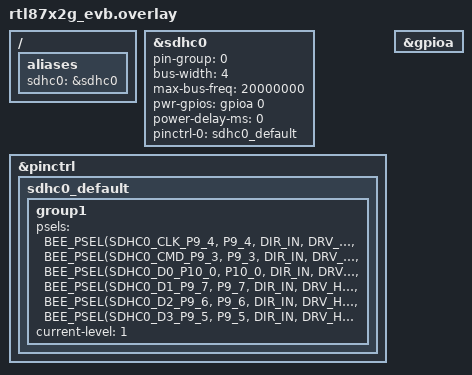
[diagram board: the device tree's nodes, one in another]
/*
 * Copyright(c) 2025, Realtek Semiconductor Corporation.
 *
 * SPDX-License-Identifier: Apache-2.0
 */

/ {
	aliases {
		sdhc0 = &sdhc0;
	};
};

&sdhc0 {
	pin-group = <0>;
	bus-width = <4>;
	max-bus-freq = <20000000>;
	pwr-gpios = <&gpioa 0 GPIO_ACTIVE_HIGH>;
	power-delay-ms = <0>;
	pinctrl-0 = <&sdhc0_default>;
	pinctrl-names = "default";
	status = "okay";
};

&pinctrl {
	sdhc0_default: sdhc0_default {
		group1 {
				psels = <BEE_PSEL(SDHC0_CLK_P9_4, P9_4, DIR_IN, DRV_HIGH, PULL_UP)>,
				<BEE_PSEL(SDHC0_CMD_P9_3, P9_3, DIR_IN, DRV_HIGH, PULL_UP)>,
				<BEE_PSEL(SDHC0_D0_P10_0, P10_0, DIR_IN, DRV_HIGH, PULL_UP)>,
				<BEE_PSEL(SDHC0_D1_P9_7, P9_7, DIR_IN, DRV_HIGH, PULL_UP)>,
				<BEE_PSEL(SDHC0_D2_P9_6, P9_6, DIR_IN, DRV_HIGH, PULL_UP)>,
				<BEE_PSEL(SDHC0_D3_P9_5, P9_5, DIR_IN, DRV_HIGH, PULL_UP)>;
				current-level = <1>;
		};
	};
};

&gpioa {
	status = "okay";
};
